# nrf9230_secure register map
Vendor: Nordic Semiconductor; Series: nRF92; File version: 1
CPU: CM33 r0p4, little endian, MPU, no FPU, 3 interrupt priority bits, 480 interrupts, 8 SAU regions
Registers are 32-bit, read-write, reset 0x0 unless marked. A register's access mark holds for its fields unless they carry their own. Offsets are from the block's base; [hi:lo] are bit positions; lines under a group give offsets from that group; {n}, {i} and the like mark numbered series; 'fields as' and 'values as' point back to an identical list.

## GLOBAL_RAMC122_NS — RAM Controller 0
Base 0x4F8DA000
Same registers: GLOBAL_RAMC123_NS 0x4F8DD000, GLOBAL_RAMC122_S 0x5F8DA000, GLOBAL_RAMC123_S 0x5F8DD000
0x500 WAITSTATES — Waitstates for read operations.
  [0] WAITSTATES — Number of waitstates for a read from the RAM.

## GLOBAL_DPPIC120_NS — Distributed programmable peripheral interconnect controller 0
Base 0x4F8E1000
Same registers: GLOBAL_DPPIC130_NS 0x4F922000, GLOBAL_DPPIC131_NS 0x4F981000, GLOBAL_DPPIC132_NS 0x4F991000, GLOBAL_DPPIC133_NS 0x4F9A1000, GLOBAL_DPPIC134_NS 0x4F9B1000, GLOBAL_DPPIC135_NS 0x4F9C1000, GLOBAL_DPPIC136_NS 0x4F9D1000, GLOBAL_DPPIC120_S 0x5F8E1000, GLOBAL_DPPIC130_S 0x5F922000, GLOBAL_DPPIC131_S 0x5F981000, GLOBAL_DPPIC132_S 0x5F991000, GLOBAL_DPPIC133_S 0x5F9A1000, GLOBAL_DPPIC134_S 0x5F9B1000, GLOBAL_DPPIC135_S 0x5F9C1000, GLOBAL_DPPIC136_S 0x5F9D1000
{0x0+8i} TASKS_CHG[{i}] (i=0..3) group — Channel group tasks
  0x00 EN wo — Description cluster: Enable channel group n
    [0] EN — Enable channel group n
      1=Trigger task
  0x04 DIS wo — Description cluster: Disable channel group n
    [0] DIS — Disable channel group n
      1=Trigger task
{0x80+8i} SUBSCRIBE_CHG[{i}] (i=0..3) group — Subscribe configuration for tasks
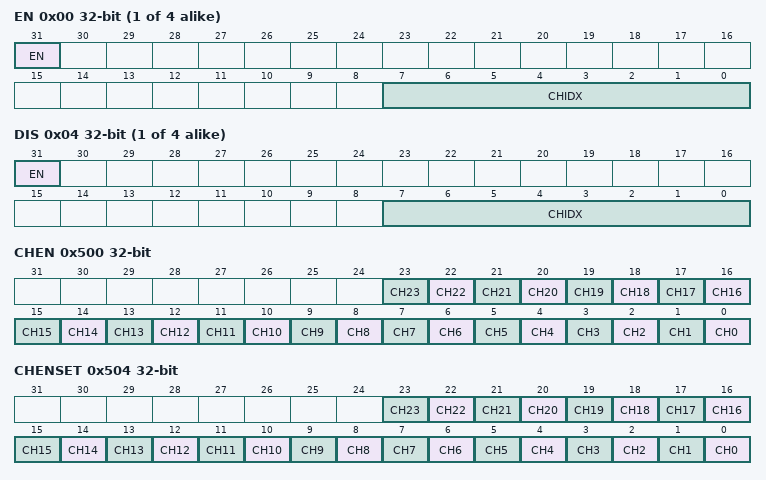
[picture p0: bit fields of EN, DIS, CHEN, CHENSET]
  0x00 EN — Description cluster: Subscribe configuration for task CHG[n].EN
    [31] EN
      0=Disabled (Disable subscription); 1=Enabled (Enable subscription)
    [7:0] CHIDX — DPPI channel that task CHG[n].EN will subscribe to
  0x04 DIS — Description cluster: Subscribe configuration for task CHG[n].DIS
    [31] EN
      values as SUBSCRIBE_CHG[0].EN.EN
    [7:0] CHIDX — DPPI channel that task CHG[n].DIS will subscribe to
0x500 CHEN — Channel enable register
  [all] fields
    0=Disabled (Disable channel); 1=Enabled (Enable channel)
  [n] CH{n} (n=0..23) — Enable or disable channel {n}
0x504 CHENSET write-1-sets — Channel enable set register
  [all] fields
    on read: 0=Disabled (Read: Channel disabled); 1=Enabled (Read: Channel enabled) | on write: 1=Set (Write: Enable channel)
  [n] CH{n} (n=0..23) — Channel {n} enable set register. Writing 0 has no effect.
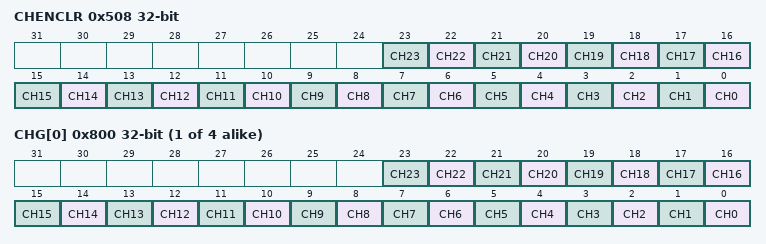
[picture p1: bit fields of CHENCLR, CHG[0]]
0x508 CHENCLR write-1-clears — Channel enable clear register
  [all] fields
    on read: 0=Disabled (Read: Channel disabled); 1=Enabled (Read: Channel enabled) | on write: 1=Clear (Write: Disable channel)
  [n] CH{n} (n=0..23) — Channel {n} enable clear register. Writing 0 has no effect.
{0x800+4i} CHG[{i}] (i=0..3) — Description collection: Channel group n Note: Writes to this register are ignored if either SUBSCRIBE_CHG[n].EN or SUBSCRIBE_CHG[n].DIS is enabled
  [all] fields
    0=Excluded; 1=Included
  [n] CH{n} (n=0..23) — Include or exclude channel {n}

## IPCMAP_S — IPCMAP APB registers
Base 0x5F923000
{0x400+8i} CHANNEL[{i}] (i=0..30) group — Unspecified
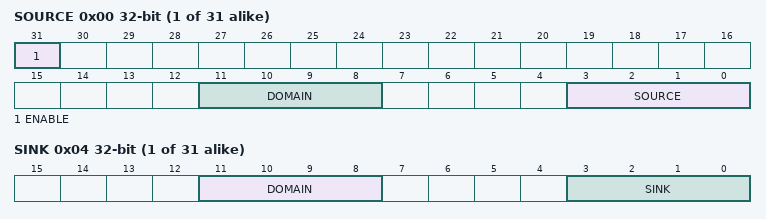
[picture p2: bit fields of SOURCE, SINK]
  0x00 SOURCE — Description cluster: The IPCT source configuration for the channel [n] from a ICPT.
    [31] ENABLE — Channel enable.
      0=Disabled (Disable channel.); 1=Enabled (Enable channel.)
    [11:8] DOMAIN — Domain identifier.
    [3:0] SOURCE — Source identification for IPC mapping.
  0x04 SINK — Description cluster: The IPCT sink configuration for the channel [n] to another ICPT.
    [11:8] DOMAIN — Domain identifier.
    [3:0] SINK — Sink identifiation for IPC mapping.

## IRQMAP_S — IRQMAP APB registers
Base 0x5F924000
{0x400+4i} IRQ[{i}] (i=0..479) group — Unspecified
  0x00 SINK — Description cluster: The interrupt sink configuration for interrupt [n] to a processor.
    [11:8] PROCESSORID — Processor identifier.

## GLOBAL_EGU130_NS — Event generator unit 0
Base 0x4F92D000
Same registers: GLOBAL_EGU130_S 0x5F92D000
{0x0+4i} TASKS_TRIGGER[{i}] (i=0..15) wo — Description collection: Trigger n for triggering the corresponding TRIGGERED[n] event
  [0] TASKS_TRIGGER — Trigger n for triggering the corresponding TRIGGERED[n] event
    1=Trigger task
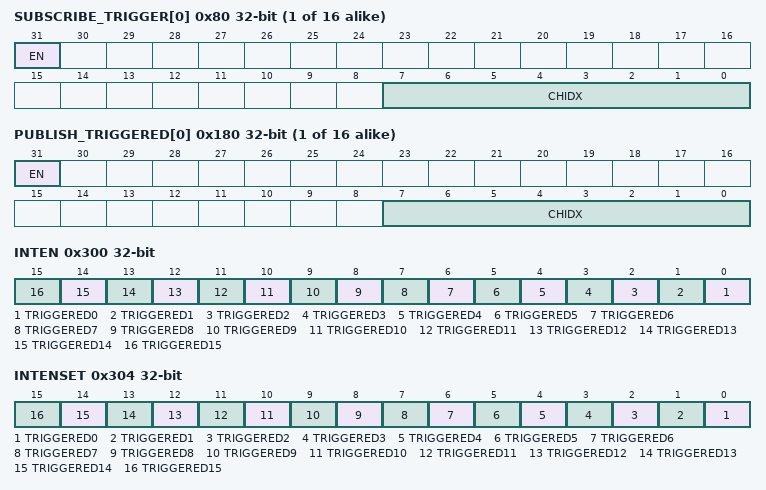
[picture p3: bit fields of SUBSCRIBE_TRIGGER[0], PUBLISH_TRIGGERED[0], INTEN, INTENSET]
{0x80+4i} SUBSCRIBE_TRIGGER[{i}] (i=0..15) — Description collection: Subscribe configuration for task TRIGGER[n]
  [31] EN
    0=Disabled (Disable subscription); 1=Enabled (Enable subscription)
  [7:0] CHIDX — DPPI channel that task TRIGGER[n] will subscribe to
{0x100+4i} EVENTS_TRIGGERED[{i}] (i=0..15) — Description collection: Event number n generated by triggering the corresponding TRIGGER[n] task
  [0] EVENTS_TRIGGERED — Event number n generated by triggering the corresponding TRIGGER[n] task
    0=NotGenerated (Event not generated); 1=Generated (Event generated)
{0x180+4i} PUBLISH_TRIGGERED[{i}] (i=0..15) — Description collection: Publish configuration for event TRIGGERED[n]
  [31] EN
    0=Disabled (Disable publishing); 1=Enabled (Enable publishing)
  [7:0] CHIDX — DPPI channel that event TRIGGERED[n] will publish to
0x300 INTEN — Enable or disable interrupt
  [all] fields
    0=Disabled; 1=Enabled
  [n] TRIGGERED{n} (n=0..15) — Enable or disable interrupt for event TRIGGERED[{n}]
0x304 INTENSET — Enable interrupt
  [all] fields
    on read: 0=Disabled (Read: Disabled); 1=Enabled (Read: Enabled) | on write: 1=Set (Enable)
  [n] TRIGGERED{n} (n=0..15) — Write '1' to enable interrupt for event TRIGGERED[{n}]
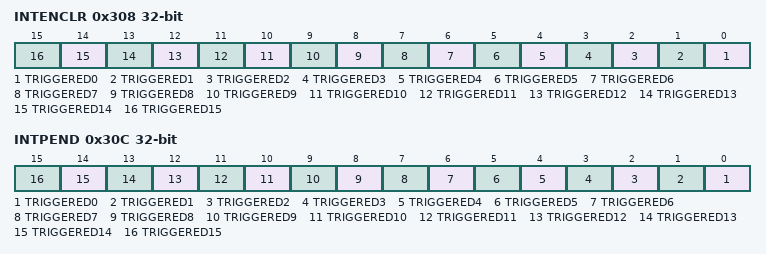
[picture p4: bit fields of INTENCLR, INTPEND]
0x308 INTENCLR — Disable interrupt
  [all] fields
    on read: 0=Disabled (Read: Disabled); 1=Enabled (Read: Enabled) | on write: 1=Clear (Disable)
  [n] TRIGGERED{n} (n=0..15) — Write '1' to disable interrupt for event TRIGGERED[{n}]
0x30C INTPEND ro — Pending interrupts
  [all] fields
    on read: 0=NotPending (Read: Not pending); 1=Pending (Read: Pending)
  [n] TRIGGERED{n} (n=0..15) — Read pending status of interrupt for event TRIGGERED[{n}]

## GLOBAL_GPIOINTERNAL_NS — GPIO Internal 0
Base 0x4F939E00
Same registers: GLOBAL_GPIOINTERNAL_S 0x5F939E00
0x40 LATCHCLRWAITCNT reset 0x2 — Select the number of wait cycles inserted on the bus when a LATCH register is cleared.
  [1:0] LATCHCLRWAITCNT
0x44 FORCELDETECTLOWCNT reset 0x8 — Select the number of cycles that LDETECT is forced low after clearing a LATCH register.
  [3:0] FORCELDETECTLOWCNT
0x48 RESET — Reset all GPIO registers.
  [0] RESET
    1=RESET (Trigger reset); 0=NA (No effect)
0x4C SENSECONFIGCHANGECNT reset 0x3 — Selects the number of cycles before the SENSE configuration takes effect when it is changed. Setting this register lower than the reset value can lead to unwanted LATCH set when SENSE and INPUT fields (PIN[n].CNF) are changed simultaneously.
  [2:0] SENSECONFIGCHANGECNT — Selects the number of cycles before the SENSE configuration takes effect when it is changed.
0x160 PCGC group — Unspecified
  0x00 TURNOFFAUTOCLOCKSOURCEREQ ro — No functionality
  {0x20+4j} PENALTY[{j}] (j=0..4) ro — Description collection: Penalty level for power/clock pair n
    [7:0] PENALTY — Penalty level
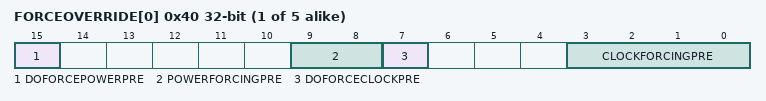
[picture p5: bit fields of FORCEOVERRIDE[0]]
  {0x40+4j} FORCEOVERRIDE[{j}] (j=0..4) ro — Description collection: Force override of power/clock pair n
    [15] DOFORCEPOWERPRE, [9:8] POWERFORCINGPRE, [7] DOFORCECLOCKPRE, [3:0] CLOCKFORCINGPRE

## Notices in the file
Copyright (c) 2010 - 2024, Nordic Semiconductor ASA
All rights reserved.
Redistribution and use in source and binary forms, with or without modification,
are permitted provided that the following conditions are met:
1. Redistributions of source code must retain the above copyright notice, this
list of conditions and the following disclaimer.
2. Redistributions in binary form, except as embedded into a Nordic
Semiconductor ASA integrated circuit in a product or a software update for
such product, must reproduce the above copyright notice, this list of
conditions and the following disclaimer in the documentation and/or other
materials provided with the distribution.
3. Neither the name of Nordic Semiconductor ASA nor the names of its
contributors may be used to endorse or promote products derived from this
software without specific prior written permission.
4. This software, with or without modification, must only be used with a
Nordic Semiconductor ASA integrated circuit.
5. Any software provided in binary form under this license must not be reverse
engineered, decompiled, modified and/or disassembled.
THIS SOFTWARE IS PROVIDED BY NORDIC SEMICONDUCTOR ASA "AS IS" AND ANY EXPRESS
OR IMPLIED WARRANTIES, INCLUDING, BUT NOT LIMITED TO, THE IMPLIED WARRANTIES
OF MERCHANTABILITY, NONINFRINGEMENT, AND FITNESS FOR A PARTICULAR PURPOSE ARE
DISCLAIMED. IN NO EVENT SHALL NORDIC SEMICONDUCTOR ASA OR CONTRIBUTORS BE
LIABLE FOR ANY DIRECT, INDIRECT, INCIDENTAL, SPECIAL, EXEMPLARY, OR
CONSEQUENTIAL DAMAGES (INCLUDING, BUT NOT LIMITED TO, PROCUREMENT OF SUBSTITUTE
GOODS OR SERVICES; LOSS OF USE, DATA, OR PROFITS; OR BUSINESS INTERRUPTION)
HOWEVER CAUSED AND ON ANY THEORY OF LIABILITY, WHETHER IN CONTRACT, STRICT
LIABILITY, OR TORT (INCLUDING NEGLIGENCE OR OTHERWISE) ARISING IN ANY WAY OUT
OF THE USE OF THIS SOFTWARE, EVEN IF ADVISED OF THE POSSIBILITY OF SUCH DAMAGE.
